AUTOSAR XML (schema 4-3-0)
standard types defined: UINT8, UINT16, UINT32, UINT64, SINT8, SINT16, SINT32, FLOAT32, FLOAT64
package /SSM_Slave_1_0/ComponentTypes
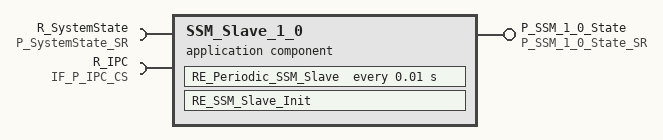
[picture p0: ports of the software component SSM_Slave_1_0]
  application sw component type SSM_Slave_1_0
    provide port P_SSM_1_0_State: nonqueued-sender-com-spec{data-element=State_1_0, init-value=constant-reference=init_State_1_0}, provided-interface=P_SSM_1_0_State_SR
    require port R_SystemState: nonqueued-receiver-com-spec{data-element=SystemState, init-value=constant-reference=init_SystemState}, required-interface=P_SystemState_SR
    require port R_IPC: client-com-spec=IPC_Write_v, required-interface=IF_P_IPC_CS
    behavior SSM_Slave_1_0_InternalBehavior: handle-termination-and-restart=NO-SUPPORT
      timing event TMT_RE_Periodic_SSM_Slave: start-on-event=RE_Periodic_SSM_Slave, period=0.01
      init event InitEvent: start-on-event=RE_SSM_Slave_Init
      port-api-options:
        enable-take-address=false, indirect-api=false, port=P_SSM_1_0_State
        enable-take-address=false, indirect-api=false, port=R_IPC
        enable-take-address=false, indirect-api=false, port=R_SystemState
      runnable RE_Periodic_SSM_Slave  # Periodic Runnable of Satellite
        data-receive-point-by-arguments:
          access REC_R_SystemState_SystemState: accessed-variable=R_SystemState.SystemState
        data-send-points:
          access SEND_P_SSM_1_0_State_State_1_0: accessed-variable=P_SSM_1_0_State.State_1_0
        sync call SC_R_IPC_IPC_Write_v: operation=R_IPC.IPC_Write_v, timeout=0
      runnable RE_SSM_Slave_Init
  swc implementation SSM_Slave_1_0_Implementation: programming-language=C, vendor-id=0, behavior=SSM_Slave_1_0_InternalBehavior
    code-descriptors:
      code Default: artifact-descriptors=autosar-engineering-object={short-label=Default, category=SWSRC}
package /SSM_Slave_1_0/Constant
  constant specification init_State_1_0: value-spec=fields=[0, [0, 0, 0]]
package /SSM_Slave_1_0/ImplementationDataTypes
  23 x impl type, all with type-emitter=RTE:
    BOOL: implementation-data-type=boolean
    SSM_CoreSlaveCoreStateDef: compu {0=SSM_SlaveCore_State_Unknown, 1=SSM_SlaveCore_State_BSP_Booting, 2=SSM_SlaveCore_State_BSP_Init_Done, 3=SSM_SlaveCore_State_Calibrated, 4=SSM_SlaveCore_State_AppInitialized, 5=SSM_SlaveCore_State_Running, 6=SSM_SlaveCore_State_MAX}, implementation-data-type=uint32
    SSM_SystemStateDef: compu {0=SSM_STATE_BOOTING, 1=SSM_STATE_IPCREADY, 2=SSM_STATE_RUNNING, 3=SSM_STATE_DEGRADED, 4=SSM_STATE_POWERINGDOWN, 5=SSM_STATE_OFF, 6=SSM_STATE_MAX}, implementation-data-type=uint32
    SSM_DegradedState: compu {0=SSM_DEGRADEDSTATE_MAX}, implementation-data-type=uint32
    SSM_ApplicationStatus: compu {0=SSM_APPSTATE_UNINIT, 1=SSM_APPSTATE_INIT, 2=SSM_APPSTATE_RUNNING, 3=SSM_APPSTATE_DEGRADED, 4=SSM_APPSTATE_STOPPED, 5=SSM_APPSTATE_MAX}, implementation-data-type=uint32
    SSM_MCU_QNX_Applications: compu {0=SSM_MCU_QNX_Application_ErrorMgr, 1=SSM_MCU_QNX_Application_PLD, 2=SSM_MCU_QNX_Application_MAX}, implementation-data-type=uint32
    SSM_MCU_3_1_Applications: compu {0=SSM_MCU_3_1_Application_ErrorMgr, 1=SSM_MCU_3_1_Application_MAX}, implementation-data-type=uint32
    SSM_MCU_3_0_Applications: compu {0=SSM_MCU_3_0_Application_ErrorMgr, 1=SSM_MCU_3_0_Application_USS, 2=SSM_MCU_3_0_Application_APA, 3=SSM_MCU_3_0_Application_CD, 4=SSM_MCU_3_0_Application_FUSION, 5=SSM_MCU_3_0_Application_MAX}, implementation-data-type=uint32
    SSM_MCU_2_1_Applications: compu {0=SSM_MCU_2_1_Application_ErrorMgr, 1=SSM_MCU_2_1_Application_HSF, 2=SSM_MCU_2_1_Application_KM, 3=SSM_MCU_2_1_Application_APStateMachine, 4=SSM_MCU_2_1_Application_DMS, 5=SSM_MCU_2_1_Application_MAX}, implementation-data-type=uint32
    SSM_MCU_2_0_Applications: compu {0=SSM_MCU_2_0_Application_ErrorMgr, 1=SSM_MCU_2_0_Application_MAX}, implementation-data-type=uint32
    SSM_MCU_1_0_Applications: compu {0=SSM_MCU_1_0_Application_VehInpAdapter, 1=SSM_MCU_1_0_Application_VehOptAdapter, 2=SSM_MCU_1_0_Application_MAX}, implementation-data-type=uint32
    SSM_MCU_QNX_LocalAppStatus_Arr: category=ARRAY
      element Elem_SSM_ApplicationStatus: array-size=3, array-size-semantics=FIXED-SIZE, implementation-data-type=SSM_ApplicationStatus
    SSM_MCU_3_1_LocalAppStatus_Arr: category=ARRAY
      element Elem_SSM_ApplicationStatus: array-size=2, array-size-semantics=FIXED-SIZE, implementation-data-type=SSM_ApplicationStatus
    SSM_MCU_3_0__LocalAppStatus_Arr: category=ARRAY
      element Elem_SSM_ApplicationStatus: array-size=6, array-size-semantics=FIXED-SIZE, implementation-data-type=SSM_ApplicationStatus
    SSM_MCU_2_1_LocalAppStatus_Arr: category=ARRAY
      element Elem_SSM_ApplicationStatus: array-size=6, array-size-semantics=FIXED-SIZE, implementation-data-type=SSM_ApplicationStatus
    SSM_MCU_2_0_LocalAppStatus_Arr: category=ARRAY
      element Elem_SSM_ApplicationStatus: array-size=2, array-size-semantics=FIXED-SIZE, implementation-data-type=SSM_ApplicationStatus
    SSM_MCU_1_0_LocalAppStatus_Arr: category=ARRAY
      element Elem_SSM_ApplicationStatus: array-size=3, array-size-semantics=FIXED-SIZE, implementation-data-type=SSM_ApplicationStatus
    SSM_QNX_CoreStatus: category=STRUCTURE
      element CoreStatus: implementation-data-type=SSM_CoreSlaveCoreStateDef
      element LocalAppStatus: implementation-data-type=SSM_MCU_QNX_LocalAppStatus_Arr
    SSM_3_1_CoreStatus: category=STRUCTURE
      element CoreStatus: implementation-data-type=SSM_CoreSlaveCoreStateDef
      element LocalAppStatus: implementation-data-type=SSM_MCU_3_1_LocalAppStatus_Arr
    SSM_3_0_CoreStatus: category=STRUCTURE
      element CoreStatus: implementation-data-type=SSM_CoreSlaveCoreStateDef
      element LocalAppStatus: implementation-data-type=SSM_MCU_2_0_LocalAppStatus_Arr
    SSM_2_1_CoreStatus: category=STRUCTURE
      element CoreStatus: implementation-data-type=SSM_CoreSlaveCoreStateDef
      element LocalAppStatus: implementation-data-type=SSM_MCU_2_1_LocalAppStatus_Arr
    SSM_2_0_CoreStatus: category=STRUCTURE
      element CoreStatus: implementation-data-type=SSM_CoreSlaveCoreStateDef
      element LocalAppStatus: implementation-data-type=SSM_MCU_2_0_LocalAppStatus_Arr
    SSM_1_0_CoreStatus: category=STRUCTURE
      element CoreStatus: implementation-data-type=SSM_CoreSlaveCoreStateDef
      element LocalAppStatus: implementation-data-type=SSM_MCU_1_0_LocalAppStatus_Arr
package /SSM_Slave_1_0/PortInterfaces
  sender receiver interface P_SSM_1_0_State_SR  # Output
    data State_1_0: type=SSM_1_0_CoreStatus
